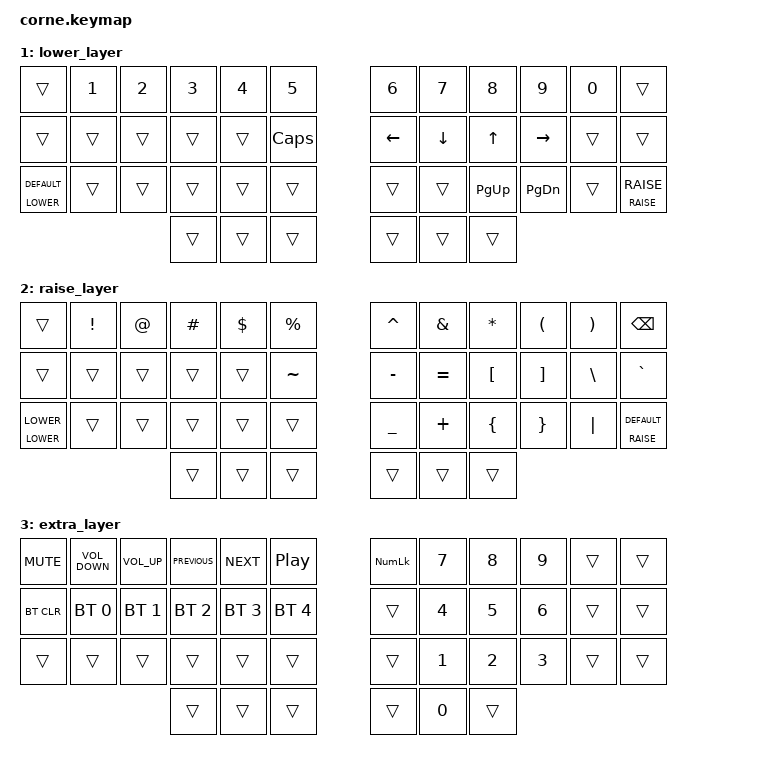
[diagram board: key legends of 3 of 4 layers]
/*
* Copyright (c) 2020 The ZMK Contributors
*
* SPDX-License-Identifier: MIT
*/

#include <behaviors.dtsi>
#include <dt-bindings/zmk/keys.h>
#include <dt-bindings/zmk/bt.h>

// Home row mods macro
#define HRML(k1,k2,k3,k4) &ht LGUI k1  &ht LALT k2  &ht LCTRL k3  &ht LSHIFT k4
#define HRMR(k1,k2,k3,k4) &ht RSHIFT k1  &ht RCTRL k2  &ht RALT k3  &ht RGUI k4

#define DEFAULT 0
#define LOWER   1
#define RAISE   2
#define EXTRA   3

/ {
	behaviors {
		ht: hold_tap {
//			label = "hold_tap";
			compatible = "zmk,behavior-hold-tap";
			#binding-cells = <2>;
			flavor = "tap-preferred";
			tapping-term-ms = <220>;
			quick-tap-ms = <150>;
			require-prior-idle-ms = <120>;
			bindings = <&kp>, <&kp>;
		};
	
		htl: hold_tap_layer {
//			label = "hold_tap_layer";
			compatible = "zmk,behavior-hold-tap";
			#binding-cells = <2>;
			flavor = "tap-preferred";
			tapping-term-ms = <220>;
			quick-tap-ms = <150>;
			require-prior-idle-ms = <120>;
			bindings = <&mo>, <&to>;
		};
	};

	conditional_layers {
		compatible = "zmk,conditional-layers";
		tri_layer {
			if-layers = <LOWER RAISE>;
			then-layer = <EXTRA>;
		};
	};

	keymap {
		compatible = "zmk,keymap";
		default_layer {
			bindings = <
				// -----------------------------------------------------------------------------------------
				// |  TAB |  Q  |  W  |  E  |  R  |  T  |   |  Y  |  U   |  I  |  O  |  P  | BSPC |
				&kp TAB   &kp Q &kp W &kp E &kp R &kp T   &kp Y &kp U  &kp I     &kp O   &kp P    &kp BSLH 
				// -----------------------------------------------------------------------------------------
				// |  ESC |  A  |  S  |  D  |  F  |  G  |   |  H  |  J   |  K  |  L  |  ;  |  '   |
				&kp ESC  HRML(A, S, D, F) &kp G   &kp H HRMR(J, K, L, SEMI) &kp SQT
				// -----------------------------------------------------------------------------------------
				// | LBKT |  Z  |  X  |  C  |  V  |  B  |   |  N  |  M   |  ,  |  .  |  /  | ESC  |
				&htl LOWER LOWER &kp Z &kp X &kp C &kp V &kp B   &kp N &kp M  &kp COMMA &kp DOT &kp FSLH &htl RAISE RAISE
				// -----------------------------------------------------------------------------------------
				//                    | GUI | LWR | SPC |   | ENT | RSE  | ALT |
				&to DEFAULT &kp BSPC &kp DELETE  &kp RET &kp SPACE &to DEFAULT
			>;
		};
		lower_layer {
			// -----------------------------------------------------------------------------------------
			// |  TAB |  1  |  2  |  3  |  4  |  5  |   |  6  |  7  |  8  |  9  |  0  | BSPC |
			// | BTCLR| BT1 | BT2 | BT3 | BT4 | BT5 |   | LFT | DWN |  UP | RGT |     |      |
			// | SHFT |     |     |     |     |     |   |     |     |     |     |     |      |
			//                    | GUI |     | SPC |   | ENT |     | ALT |
			bindings = <
				&trans &kp N1       &kp N2       &kp N3       &kp N4       &kp N5         &kp N6   &kp N7   &kp N8 &kp N9    &kp N0 &trans
				&trans  &trans  &trans   &trans   &trans  &kp CAPS &kp LEFT &kp DOWN &kp UP &kp RIGHT &trans &trans
				&htl LOWER DEFAULT  &trans       &trans   &trans    &trans      &trans         &trans   &trans   &kp PAGE_UP &kp PAGE_DOWN &trans &htl RAISE RAISE
				&trans     &trans       &trans      &trans  &trans   &trans
			>;
		};

		raise_layer {
			// -----------------------------------------------------------------------------------------
			// |  TAB |  !  |  @  |  #  |  $  |  %  |   |  ^  |  &  |  *  |  (  |  )  | BSPC |
			// | CTRL |     |     |     |     |     |   |  -  |  =  |  [  |  ]  |  \  |  `   |
			// | SHFT |     |     |     |     |     |   |  _  |  +  |  {  |  }  | "|" |  ~   |
			//                    | GUI |     | SPC |   | ENT |     | ALT |
			bindings = <
				&trans &kp EXCL &kp AT &kp HASH &kp DLLR &kp PRCNT   &kp CARET &kp AMPS  &kp ASTRK &kp LPAR &kp RPAR &kp BSPC
				&trans &trans   &trans &trans   &trans   &kp TILDE   &kp MINUS &kp EQUAL &kp LBKT  &kp RBKT &kp BSLH &kp GRAVE
				&htl LOWER LOWER &trans   &trans &trans   &trans   &trans      &kp UNDER &kp PLUS  &kp LBRC  &kp RBRC &kp PIPE &htl RAISE DEFAULT 
				&trans &trans   &trans  &trans   &trans    &trans
			>;
		};

		extra_layer {
			// -----------------------------------------------------------------------------------------
			// |  TAB |  !  |  @  |  #  |  $  |  %  |   |  ^  |  &  |  *  |  (  |  )  | BSPC |
			// | CTRL |     |     |     |     |     |   |  -  |  =  |  [  |  ]  |  \  |  `   |
			// | SHFT |     |     |     |     |     |   |  _  |  +  |  {  |  }  | "|" |  ~   |
			//                    | GUI |     | SPC |   | ENT |     | ALT |
			bindings = <
				&kp C_MUTE &kp C_VOLUME_DOWN &kp C_VOLUME_UP &kp C_PREVIOUS &kp C_NEXT &kp C_PLAY_PAUSE &kp KP_NUMLOCK &kp N7 &kp N8 &kp N9 &trans &trans
				&bt BT_CLR &bt BT_SEL 0 &bt BT_SEL 1 &bt BT_SEL 2 &bt BT_SEL 3 &bt BT_SEL 4  &trans &kp N4 &kp N5 &kp N6 &trans   &trans 
				&trans &trans   &trans &trans   &trans   &trans      &trans &kp N1 &kp N2 &kp N3 &trans &trans
				&trans &trans   &trans  &trans   &kp N0 &trans
			>;
		};
	};
};
